# COMPUTE_CLUSTER0_A72SS0_COMMON_ECC_AGGR register map
Vendor: Texas Instruments
Peripheral module from a debugger description file (folder J7VCL).
Registers are 32-bit, access not given, reset 0x0 unless marked. A register's access mark holds for its fields unless they carry their own. Offsets are as the file gives them; lines under a group give offsets from that group; [hi:lo] are bit positions; {n}, {i} and the like mark numbered series; 'fields as' and 'values as' point back to an identical list; <NAME> marks a mode.

## COMPUTE_CLUSTER0_A72SS0_COMMON_ECC_AGGR
0x00 A72SS_CLUSTER_ECC_REV ro reset 0x66A0EA00 — IP revision register.
  [31:0] REV — TI internal data. Identifies revision of peripheral.
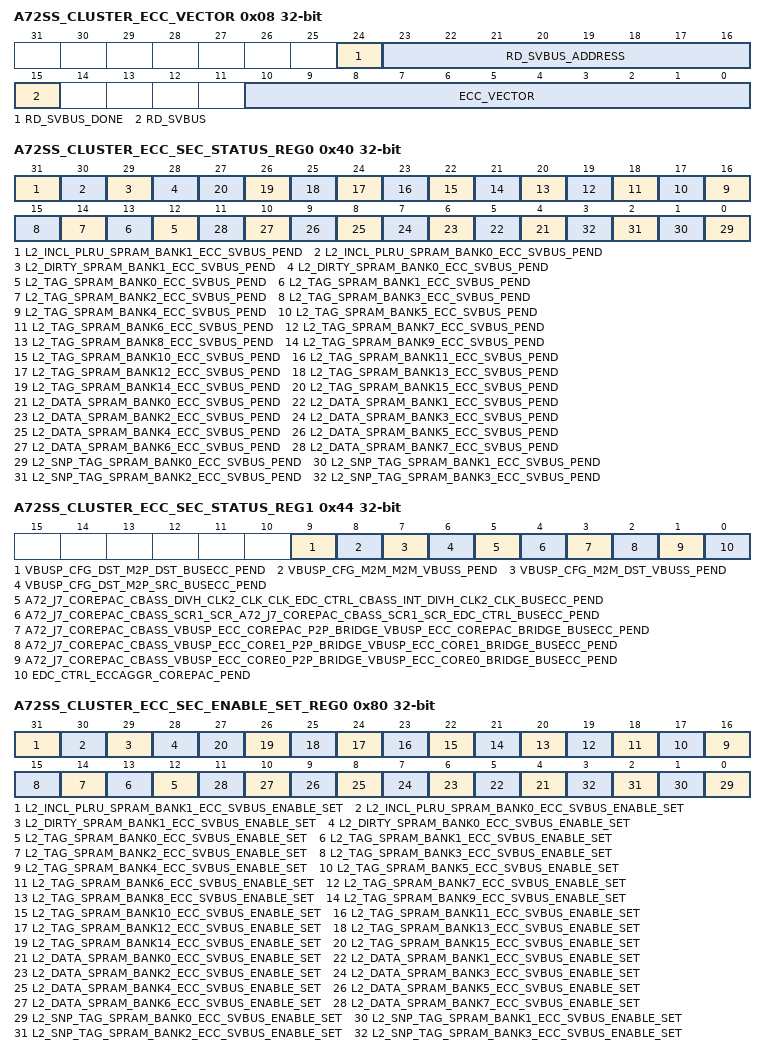
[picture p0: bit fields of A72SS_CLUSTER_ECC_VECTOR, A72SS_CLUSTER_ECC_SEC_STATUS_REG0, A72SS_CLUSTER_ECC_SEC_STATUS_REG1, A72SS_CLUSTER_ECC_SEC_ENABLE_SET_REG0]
0x08 A72SS_CLUSTER_ECC_VECTOR — ECC vector register.
  [24] RD_SVBUS_DONE — Status to indicate if read on serial VBUS is complete, write of any value will clear this bit. (access RW1C)
  [23:16] RD_SVBUS_ADDRESS rw — Read address
  [15] RD_SVBUS — Write 1 to trigger a read on the serial VBUS (access RW1S)
  [10:0] ECC_VECTOR rw — Value written to select the corresponding ECC RAM for control or status
0x0C A72SS_CLUSTER_ECC_STAT ro reset 0x2A — Misc status register.
  [10:0] NUM_RAMS — Indicates the number of RAMs serviced by the ECC aggregator
0x3C A72SS_CLUSTER_ECC_SEC_EOI_REG — SEC EOI register. The EOI register is used to re-trigger the pulse interrupt signal to ensure that any nested interrupt events are serviced. The software interrupt handler must write to the EOI register at the end of the current interrupt processing routine, so that new events can re-trigger the pulse interrupt signal again. For level interrupt signals the EOI register is not functional and must not be used.
  [0] EOI_WR — EOI value (access RW1S)
0x40 A72SS_CLUSTER_ECC_SEC_STATUS_REG0 — SEC interrupt status register 0.
  [31] L2_INCL_PLRU_SPRAM_BANK1_ECC_SVBUS_PEND — Interrupt pending status for l2_incl_plru_spram_bank1_ecc_svbus_pend (access RW1S)
  [30] L2_INCL_PLRU_SPRAM_BANK0_ECC_SVBUS_PEND — Interrupt pending status for l2_incl_plru_spram_bank0_ecc_svbus_pend (access RW1S)
  [29] L2_DIRTY_SPRAM_BANK1_ECC_SVBUS_PEND — Interrupt pending status for l2_dirty_spram_bank1_ecc_svbus_pend (access RW1S)
  [28] L2_DIRTY_SPRAM_BANK0_ECC_SVBUS_PEND — Interrupt pending status for l2_dirty_spram_bank0_ecc_svbus_pend (access RW1S)
  [n+12] L2_TAG_SPRAM_BANK{n}_ECC_SVBUS_PEND (n=0..15) — Interrupt pending status for l2_tag_spram_bank{n}_ecc_svbus_pend (access RW1S)
  [n+4] L2_DATA_SPRAM_BANK{n}_ECC_SVBUS_PEND (n=0..7) — Interrupt pending status for l2_data_spram_bank{n}_ecc_svbus_pend (access RW1S)
  [n] L2_SNP_TAG_SPRAM_BANK{n}_ECC_SVBUS_PEND (n=0..3) — Interrupt pending status for l2_snp_tag_spram_bank{n}_ecc_svbus_pend (access RW1S)
0x44 A72SS_CLUSTER_ECC_SEC_STATUS_REG1 — SEC interrupt status register 1.
  [9] VBUSP_CFG_DST_M2P_DST_BUSECC_PEND — Interrupt pending status for vbusp_cfg_dst_m2p_dst_busecc_pend (access RW1S)
  [8] VBUSP_CFG_M2M_M2M_VBUSS_PEND — Interrupt pending status for vbusp_cfg_m2m_m2m_vbuss_pend (access RW1S)
  [7] VBUSP_CFG_M2M_DST_VBUSS_PEND — Interrupt pending status for vbusp_cfg_m2m_dst_vbuss_pend (access RW1S)
  [6] VBUSP_CFG_DST_M2P_SRC_BUSECC_PEND — Interrupt pending status for vbusp_cfg_dst_m2p_src_busecc_pend (access RW1S)
  [5] A72_J7_COREPAC_CBASS_DIVH_CLK2_CLK_CLK_EDC_CTRL_CBASS_INT_DIVH_CLK2_CLK_BUSECC_PEND — Interrupt pending status for a72_j7_corepac_cbass_divh_clk2_clk_clk_edc_ctrl_cbass_int_divh_clk2_clk_busecc_pend (access RW1S)
  [4] A72_J7_COREPAC_CBASS_SCR1_SCR_A72_J7_COREPAC_CBASS_SCR1_SCR_EDC_CTRL_BUSECC_PEND — Interrupt pending status for a72_j7_corepac_cbass_scr1_scr_a72_j7_corepac_cbass_scr1_scr_edc_ctrl_busecc_pend (access RW1S)
  [3] A72_J7_COREPAC_CBASS_VBUSP_ECC_COREPAC_P2P_BRIDGE_VBUSP_ECC_COREPAC_BRIDGE_BUSECC_PEND — Interrupt pending status for a72_j7_corepac_cbass_vbusp_ecc_corepac_p2p_bridge_vbusp_ecc_corepac_bridge_busecc_pend (access RW1S)
  [2] A72_J7_COREPAC_CBASS_VBUSP_ECC_CORE1_P2P_BRIDGE_VBUSP_ECC_CORE1_BRIDGE_BUSECC_PEND — Interrupt pending status for a72_j7_corepac_cbass_vbusp_ecc_core1_p2p_bridge_vbusp_ecc_core1_bridge_busecc_pend (access RW1S)
  [1] A72_J7_COREPAC_CBASS_VBUSP_ECC_CORE0_P2P_BRIDGE_VBUSP_ECC_CORE0_BRIDGE_BUSECC_PEND — Interrupt pending status for a72_j7_corepac_cbass_vbusp_ecc_core0_p2p_bridge_vbusp_ecc_core0_bridge_busecc_pend (access RW1S)
  [0] EDC_CTRL_ECCAGGR_COREPAC_PEND — Interrupt pending status for edc_ctrl_eccaggr_corepac_pend (access RW1S)
0x80 A72SS_CLUSTER_ECC_SEC_ENABLE_SET_REG0 — SEC interrupt enable set register 0.
  [31] L2_INCL_PLRU_SPRAM_BANK1_ECC_SVBUS_ENABLE_SET — Interrupt enable set for l2_incl_plru_spram_bank1_ecc_svbus_pend (access RW1S)
  [30] L2_INCL_PLRU_SPRAM_BANK0_ECC_SVBUS_ENABLE_SET — Interrupt enable set for l2_incl_plru_spram_bank0_ecc_svbus_pend (access RW1S)
  [29] L2_DIRTY_SPRAM_BANK1_ECC_SVBUS_ENABLE_SET — Interrupt enable set for l2_dirty_spram_bank1_ecc_svbus_pend (access RW1S)
  [28] L2_DIRTY_SPRAM_BANK0_ECC_SVBUS_ENABLE_SET — Interrupt enable set for l2_dirty_spram_bank0_ecc_svbus_pend (access RW1S)
  [n+12] L2_TAG_SPRAM_BANK{n}_ECC_SVBUS_ENABLE_SET (n=0..15) — Interrupt enable set for l2_tag_spram_bank{n}_ecc_svbus_pend (access RW1S)
  [n+4] L2_DATA_SPRAM_BANK{n}_ECC_SVBUS_ENABLE_SET (n=0..7) — Interrupt enable set for l2_data_spram_bank{n}_ecc_svbus_pend (access RW1S)
  [n] L2_SNP_TAG_SPRAM_BANK{n}_ECC_SVBUS_ENABLE_SET (n=0..3) — Interrupt enable set for l2_snp_tag_spram_bank{n}_ecc_svbus_pend (access RW1S)
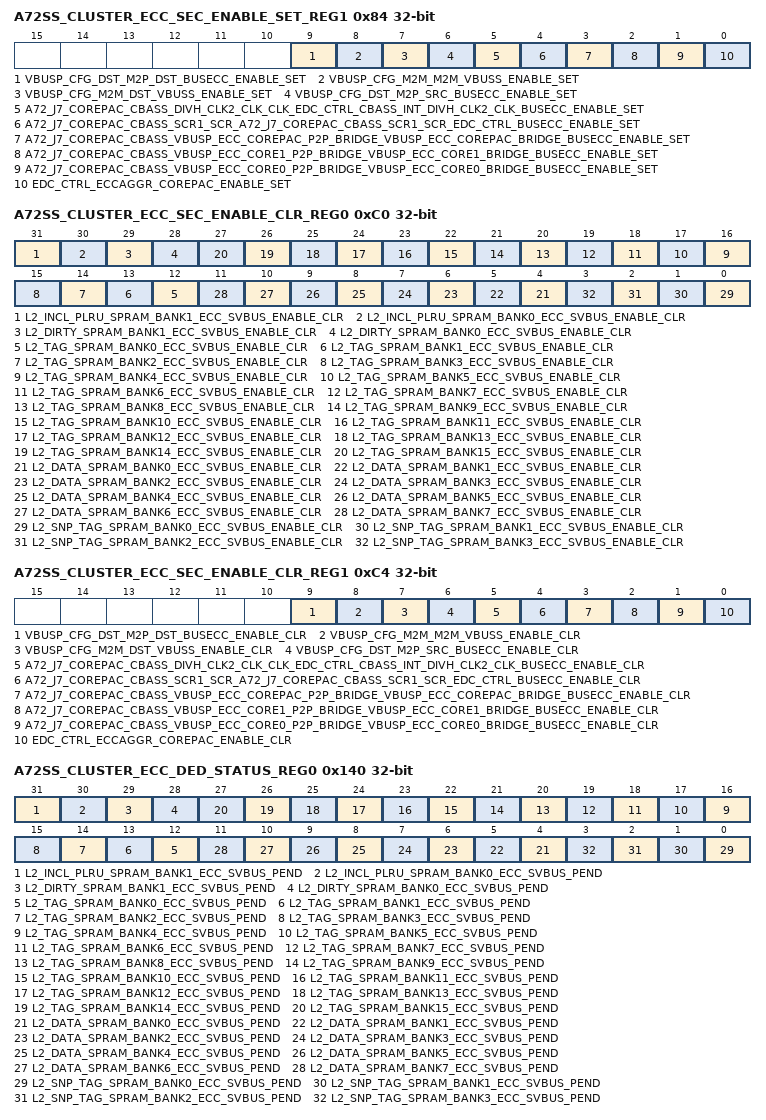
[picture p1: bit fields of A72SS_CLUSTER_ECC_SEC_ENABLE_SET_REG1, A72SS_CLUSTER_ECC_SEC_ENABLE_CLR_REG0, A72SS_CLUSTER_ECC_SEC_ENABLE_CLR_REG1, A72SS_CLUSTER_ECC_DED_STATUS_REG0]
0x84 A72SS_CLUSTER_ECC_SEC_ENABLE_SET_REG1 — SEC interrupt enable set register 1.
  [9] VBUSP_CFG_DST_M2P_DST_BUSECC_ENABLE_SET — Interrupt enable set for vbusp_cfg_dst_m2p_dst_busecc_pend (access RW1S)
  [8] VBUSP_CFG_M2M_M2M_VBUSS_ENABLE_SET — Interrupt enable set for vbusp_cfg_m2m_m2m_vbuss_pend (access RW1S)
  [7] VBUSP_CFG_M2M_DST_VBUSS_ENABLE_SET — Interrupt enable set for vbusp_cfg_m2m_dst_vbuss_pend (access RW1S)
  [6] VBUSP_CFG_DST_M2P_SRC_BUSECC_ENABLE_SET — Interrupt enable set for vbusp_cfg_dst_m2p_src_busecc_pend (access RW1S)
  [5] A72_J7_COREPAC_CBASS_DIVH_CLK2_CLK_CLK_EDC_CTRL_CBASS_INT_DIVH_CLK2_CLK_BUSECC_ENABLE_SET — Interrupt enable set for a72_j7_corepac_cbass_divh_clk2_clk_clk_edc_ctrl_cbass_int_divh_clk2_clk_busecc_pend (access RW1S)
  [4] A72_J7_COREPAC_CBASS_SCR1_SCR_A72_J7_COREPAC_CBASS_SCR1_SCR_EDC_CTRL_BUSECC_ENABLE_SET — Interrupt enable set for a72_j7_corepac_cbass_scr1_scr_a72_j7_corepac_cbass_scr1_scr_edc_ctrl_busecc_pend (access RW1S)
  [3] A72_J7_COREPAC_CBASS_VBUSP_ECC_COREPAC_P2P_BRIDGE_VBUSP_ECC_COREPAC_BRIDGE_BUSECC_ENABLE_SET — Interrupt enable set for a72_j7_corepac_cbass_vbusp_ecc_corepac_p2p_bridge_vbusp_ecc_corepac_bridge_busecc_pend (access RW1S)
  [2] A72_J7_COREPAC_CBASS_VBUSP_ECC_CORE1_P2P_BRIDGE_VBUSP_ECC_CORE1_BRIDGE_BUSECC_ENABLE_SET — Interrupt enable set for a72_j7_corepac_cbass_vbusp_ecc_core1_p2p_bridge_vbusp_ecc_core1_bridge_busecc_pend (access RW1S)
  [1] A72_J7_COREPAC_CBASS_VBUSP_ECC_CORE0_P2P_BRIDGE_VBUSP_ECC_CORE0_BRIDGE_BUSECC_ENABLE_SET — Interrupt enable set for a72_j7_corepac_cbass_vbusp_ecc_core0_p2p_bridge_vbusp_ecc_core0_bridge_busecc_pend (access RW1S)
  [0] EDC_CTRL_ECCAGGR_COREPAC_ENABLE_SET — Interrupt enable set for edc_ctrl_eccaggr_corepac_pend (access RW1S)
0xC0 A72SS_CLUSTER_ECC_SEC_ENABLE_CLR_REG0 — SEC interrupt enable clear register 0.
  [31] L2_INCL_PLRU_SPRAM_BANK1_ECC_SVBUS_ENABLE_CLR — Interrupt enable clear for l2_incl_plru_spram_bank1_ecc_svbus_pend (access RW1C)
  [30] L2_INCL_PLRU_SPRAM_BANK0_ECC_SVBUS_ENABLE_CLR — Interrupt enable clear for l2_incl_plru_spram_bank0_ecc_svbus_pend (access RW1C)
  [29] L2_DIRTY_SPRAM_BANK1_ECC_SVBUS_ENABLE_CLR — Interrupt enable clear for l2_dirty_spram_bank1_ecc_svbus_pend (access RW1C)
  [28] L2_DIRTY_SPRAM_BANK0_ECC_SVBUS_ENABLE_CLR — Interrupt enable clear for l2_dirty_spram_bank0_ecc_svbus_pend (access RW1C)
  [n+12] L2_TAG_SPRAM_BANK{n}_ECC_SVBUS_ENABLE_CLR (n=0..15) — Interrupt enable clear for l2_tag_spram_bank{n}_ecc_svbus_pend (access RW1C)
  [n+4] L2_DATA_SPRAM_BANK{n}_ECC_SVBUS_ENABLE_CLR (n=0..7) — Interrupt enable clear for l2_data_spram_bank{n}_ecc_svbus_pend (access RW1C)
  [n] L2_SNP_TAG_SPRAM_BANK{n}_ECC_SVBUS_ENABLE_CLR (n=0..3) — Interrupt enable clear for l2_snp_tag_spram_bank{n}_ecc_svbus_pend (access RW1C)
0xC4 A72SS_CLUSTER_ECC_SEC_ENABLE_CLR_REG1 — SEC interrupt enable clear register 1.
  [9] VBUSP_CFG_DST_M2P_DST_BUSECC_ENABLE_CLR — Interrupt enable clear for vbusp_cfg_dst_m2p_dst_busecc_pend (access RW1C)
  [8] VBUSP_CFG_M2M_M2M_VBUSS_ENABLE_CLR — Interrupt enable clear for vbusp_cfg_m2m_m2m_vbuss_pend (access RW1C)
  [7] VBUSP_CFG_M2M_DST_VBUSS_ENABLE_CLR — Interrupt enable clear for vbusp_cfg_m2m_dst_vbuss_pend (access RW1C)
  [6] VBUSP_CFG_DST_M2P_SRC_BUSECC_ENABLE_CLR — Interrupt enable clear for vbusp_cfg_dst_m2p_src_busecc_pend (access RW1C)
  [5] A72_J7_COREPAC_CBASS_DIVH_CLK2_CLK_CLK_EDC_CTRL_CBASS_INT_DIVH_CLK2_CLK_BUSECC_ENABLE_CLR — Interrupt enable clear for a72_j7_corepac_cbass_divh_clk2_clk_clk_edc_ctrl_cbass_int_divh_clk2_clk_busecc_pend (access RW1C)
  [4] A72_J7_COREPAC_CBASS_SCR1_SCR_A72_J7_COREPAC_CBASS_SCR1_SCR_EDC_CTRL_BUSECC_ENABLE_CLR — Interrupt enable clear for a72_j7_corepac_cbass_scr1_scr_a72_j7_corepac_cbass_scr1_scr_edc_ctrl_busecc_pend (access RW1C)
  [3] A72_J7_COREPAC_CBASS_VBUSP_ECC_COREPAC_P2P_BRIDGE_VBUSP_ECC_COREPAC_BRIDGE_BUSECC_ENABLE_CLR — Interrupt enable clear for a72_j7_corepac_cbass_vbusp_ecc_corepac_p2p_bridge_vbusp_ecc_corepac_bridge_busecc_pend (access RW1C)
  [2] A72_J7_COREPAC_CBASS_VBUSP_ECC_CORE1_P2P_BRIDGE_VBUSP_ECC_CORE1_BRIDGE_BUSECC_ENABLE_CLR — Interrupt enable clear for a72_j7_corepac_cbass_vbusp_ecc_core1_p2p_bridge_vbusp_ecc_core1_bridge_busecc_pend (access RW1C)
  [1] A72_J7_COREPAC_CBASS_VBUSP_ECC_CORE0_P2P_BRIDGE_VBUSP_ECC_CORE0_BRIDGE_BUSECC_ENABLE_CLR — Interrupt enable clear for a72_j7_corepac_cbass_vbusp_ecc_core0_p2p_bridge_vbusp_ecc_core0_bridge_busecc_pend (access RW1C)
  [0] EDC_CTRL_ECCAGGR_COREPAC_ENABLE_CLR — Interrupt enable clear for edc_ctrl_eccaggr_corepac_pend (access RW1C)
0x13C A72SS_CLUSTER_ECC_DED_EOI_REG — DED EOI register. The EOI register is used to re-trigger the pulse interrupt signal to ensure that any nested interrupt events are serviced. The software interrupt handler must write to the EOI register at the end of the current interrupt processing routine, so that new events can re-trigger the pulse interrupt signal again. For level interrupt signals the EOI register is not functional and must not be used.
  [0] EOI_WR — EOI value (access RW1S)
0x140 A72SS_CLUSTER_ECC_DED_STATUS_REG0 — DED interrupt status register 0.
  fields as A72SS_CLUSTER_ECC_SEC_STATUS_REG0
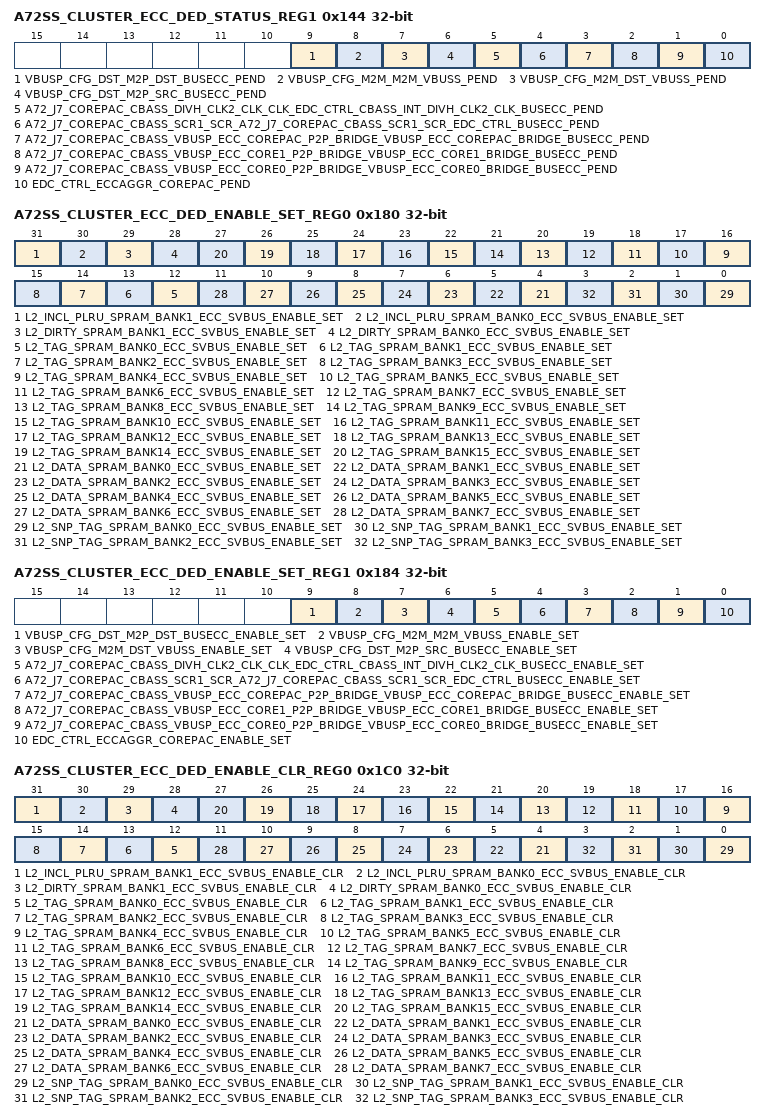
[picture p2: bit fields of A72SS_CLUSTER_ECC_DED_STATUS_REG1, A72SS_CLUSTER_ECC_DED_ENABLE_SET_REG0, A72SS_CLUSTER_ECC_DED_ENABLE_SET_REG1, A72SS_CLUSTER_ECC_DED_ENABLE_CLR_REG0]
0x144 A72SS_CLUSTER_ECC_DED_STATUS_REG1 — DED interrupt status register 1.
  fields as A72SS_CLUSTER_ECC_SEC_STATUS_REG1
0x180 A72SS_CLUSTER_ECC_DED_ENABLE_SET_REG0 — DED interrupt enable set register 0.
  fields as A72SS_CLUSTER_ECC_SEC_ENABLE_SET_REG0
0x184 A72SS_CLUSTER_ECC_DED_ENABLE_SET_REG1 — DED interrupt enable set register 1.
  [9] VBUSP_CFG_DST_M2P_DST_BUSECC_ENABLE_SET — Interrupt enable set for vbusp_cfg_dst_m2p_dst_busecc_pend (access RW1S)
  [8] VBUSP_CFG_M2M_M2M_VBUSS_ENABLE_SET — Interrupt enable set for vbusp_cfg_m2m_m2m_vbuss_pend (access RW1S)
  [7] VBUSP_CFG_M2M_DST_VBUSS_ENABLE_SET — Interrupt enable set for vbusp_cfg_m2m_dst_vbuss_pend (access RW1S)
  [6] VBUSP_CFG_DST_M2P_SRC_BUSECC_ENABLE_SET — Interrupt enable set for vbusp_cfg_dst_m2p_src_busecc_pend (access RW1S)
  [5] A72_J7_COREPAC_CBASS_DIVH_CLK2_CLK_CLK_EDC_CTRL_CBASS_INT_DIVH_CLK2_CLK_BUSECC_ENABLE_SET — Interrupt enable set for a72_j7_corepac_cbass_divh_clk2_clk_clk_edc_ctrl_cbass_int_divh_clk2_clk_busecc_pend (access RW1S)
  [4] A72_J7_COREPAC_CBASS_SCR1_SCR_A72_J7_COREPAC_CBASS_SCR1_SCR_EDC_CTRL_BUSECC_ENABLE_SET — Interrupt enable set for a72_j7_corepac_cbass_scr1_scr_a72_j7_corepac_cbass_scr1_scr_edc_ctrl_busecc_pend (access RW1S)
  [3] A72_J7_COREPAC_CBASS_VBUSP_ECC_COREPAC_P2P_BRIDGE_VBUSP_ECC_COREPAC_BRIDGE_BUSECC_ENABLE_SET — Interrupt enable set for a72_j7_corepac_cbass_vbusp_ecc_corepac_p2p_bridge_vbusp_ecc_corepac_bridge_busecc_pend (access RW1S)
  [2] A72_J7_COREPAC_CBASS_VBUSP_ECC_CORE1_P2P_BRIDGE_VBUSP_ECC_CORE1_BRIDGE_BUSECC_ENABLE_SET — Interrupt enable set for a72_j7_corepac_cbass_vbusp_ecc_core1_p2p_bridge_vbusp_ecc_core1_bridge_busecc_pend (access RW1S)
  [1] A72_J7_COREPAC_CBASS_VBUSP_ECC_CORE0_P2P_BRIDGE_VBUSP_ECC_CORE0_BRIDGE_BUSECC_ENABLE_SET — Interrupt enable set for a72_j7_corepac_cbass_vbusp_ecc_core0_p2p_bridge_vbusp_ecc_core0_bridge_busecc_pend (access RW1S)
  [0] EDC_CTRL_ECCAGGR_COREPAC_ENABLE_SET — Interrupt Enable Set Register for edc_ctrl_eccaggr_corepac_pend (access RW1S)
0x1C0 A72SS_CLUSTER_ECC_DED_ENABLE_CLR_REG0 — DED interrupt enable clear register 0.
  fields as A72SS_CLUSTER_ECC_SEC_ENABLE_CLR_REG0
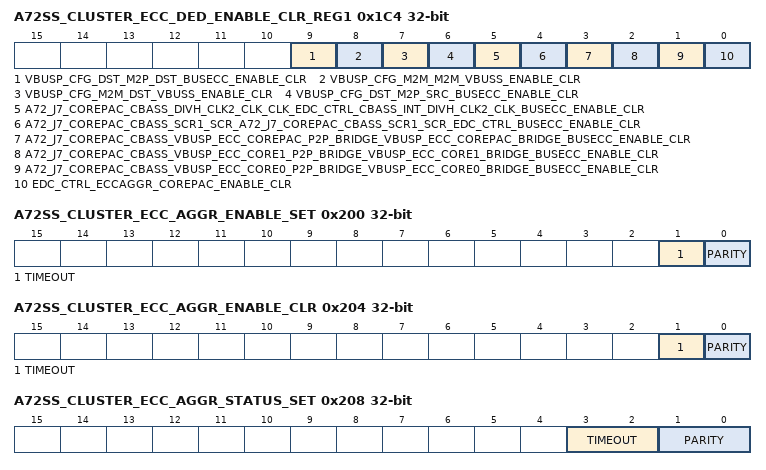
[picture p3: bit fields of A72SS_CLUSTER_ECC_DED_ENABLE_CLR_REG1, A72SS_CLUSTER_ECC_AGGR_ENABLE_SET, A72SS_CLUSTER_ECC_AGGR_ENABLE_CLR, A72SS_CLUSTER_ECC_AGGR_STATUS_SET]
0x1C4 A72SS_CLUSTER_ECC_DED_ENABLE_CLR_REG1 — DED interrupt enable clear register 1.
  fields as A72SS_CLUSTER_ECC_SEC_ENABLE_CLR_REG1
0x200 A72SS_CLUSTER_ECC_AGGR_ENABLE_SET — AGGR interrupt enable set register.
  [1] TIMEOUT — Interrupt enable set for svbus timeout errors (access RW1S)
  [0] PARITY — Interrupt enable set for parity errors (access RW1S)
0x204 A72SS_CLUSTER_ECC_AGGR_ENABLE_CLR — AGGR interrupt enable clear register.
  [1] TIMEOUT — Interrupt enable clear for svbus timeout errors (access RW1C)
  [0] PARITY — Interrupt enable clear for parity errors (access RW1C)
0x208 A72SS_CLUSTER_ECC_AGGR_STATUS_SET — AGGR interrupt status set register.
  [3:2] TIMEOUT — Interrupt status set for svbus timeout errors (access RWincr)
  [1:0] PARITY — Interrupt status set for parity errors (access RWincr)
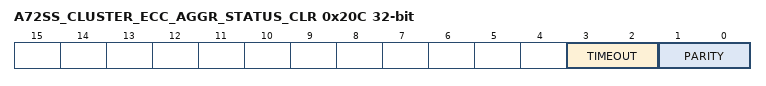
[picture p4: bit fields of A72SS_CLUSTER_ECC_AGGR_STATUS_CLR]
0x20C A72SS_CLUSTER_ECC_AGGR_STATUS_CLR — AGGR interrupt status clear register.
  [3:2] TIMEOUT — Interrupt status clear for svbus timeout errors (access RWdecr)
  [1:0] PARITY — Interrupt status clear for parity errors (access RWdecr)
